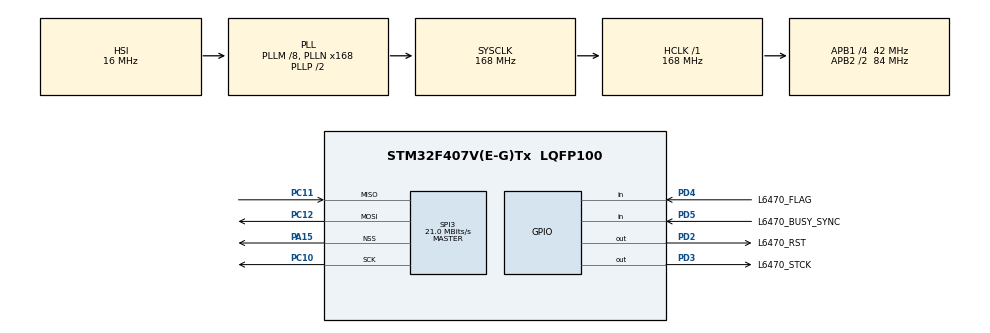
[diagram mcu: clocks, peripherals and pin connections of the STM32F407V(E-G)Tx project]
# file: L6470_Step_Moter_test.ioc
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Mcu.Family=STM32F4
Mcu.Name=STM32F407V(E-G)Tx
Mcu.Package=LQFP100
NVIC.PriorityGroup=NVIC_PRIORITYGROUP_4
PA13.Mode=Serial_Wire
PA13.Signal=SYS_JTMS-SWDIO
PA14.Mode=Serial_Wire
PA14.Signal=SYS_JTCK-SWCLK
PA15.Mode=NSS_Signal_Hard_Output
PA15.Signal=SPI3_NSS
PC10.Mode=Full_Duplex_Master
PC10.Signal=SPI3_SCK
PC11.Mode=Full_Duplex_Master
PC11.Signal=SPI3_MISO
PC12.Mode=Full_Duplex_Master
PC12.Signal=SPI3_MOSI
PC14-OSC32_IN.Mode=LSE-External-Clock-Source
PC14-OSC32_IN.Signal=RCC_OSC32_IN
PC15-OSC32_OUT.Mode=LSE-External-Clock-Source
PC15-OSC32_OUT.Signal=RCC_OSC32_OUT
PD2.GPIO_Label=L6470_RST
PD2.Signal=GPIO_Output
PD3.GPIO_Label=L6470_STCK
PD3.GPIO_Speed=GPIO_SPEED_FREQ_VERY_HIGH
PD3.Signal=GPIO_Output
PD4.GPIO_Label=L6470_FLAG
PD4.Signal=GPIO_Input
PD5.GPIO_Label=L6470_BUSY_SYNC
PD5.Signal=GPIO_Input
PH0-OSC_IN.Mode=HSE-External-Oscillator
PH0-OSC_IN.Signal=RCC_OSC_IN
PH1-OSC_OUT.Mode=HSE-External-Oscillator
PH1-OSC_OUT.Signal=RCC_OSC_OUT
ProjectManager.HeapSize=0x200
ProjectManager.StackSize=0x400
ProjectManager.TargetToolchain=STM32CubeIDE
RCC.48MHZClocksFreq_Value=84000000
RCC.AHBFreq_Value=168000000
RCC.APB1CLKDivider=RCC_HCLK_DIV4
RCC.APB1Freq_Value=42000000
RCC.APB1TimFreq_Value=84000000
RCC.APB2CLKDivider=RCC_HCLK_DIV2
RCC.APB2Freq_Value=84000000
RCC.APB2TimFreq_Value=168000000
RCC.CortexFreq_Value=168000000
RCC.HCLKFreq_Value=168000000
RCC.HSE_VALUE=8000000
RCC.HSI_VALUE=16000000
RCC.LSE_VALUE=32768
RCC.PLLM=8
RCC.PLLN=168
RCC.SYSCLKFreq_VALUE=168000000
RCC.SYSCLKSource=RCC_SYSCLKSOURCE_PLLCLK
RCC.VCOOutputFreq_Value=336000000
SPI3.CalculateBaudRate=21.0 MBits/s
SPI3.Direction=SPI_DIRECTION_2LINES
SPI3.Mode=SPI_MODE_MASTER
SPI3.VirtualNSS=VM_NSSHARD
SPI3.VirtualType=VM_MASTER
board=custom

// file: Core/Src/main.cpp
/* USER CODE BEGIN Header */
/**
  ******************************************************************************
  * @file           : main.c
  * @brief          : Main program body
  ******************************************************************************
  * @attention
  *
  * Copyright (c) 2023 STMicroelectronics.
  * All rights reserved.
  *
  * This software is licensed under terms that can be found in the LICENSE file
  * in the root directory of this software component.
  * If no LICENSE file comes with this software, it is provided AS-IS.
  *
  ******************************************************************************
  */
/* USER CODE END Header */
#include "main.h"

/* USER CODE BEGIN Includes */
#include <L6470.h>
/* USER CODE END Includes */

SPI_HandleTypeDef hspi3;

void SystemClock_Config(void);
static void MX_GPIO_Init(void);
static void MX_SPI3_Init(void);

int main(void)
{

  /* MCU Configuration--------------------------------------------------------*/

  /* Reset of all peripherals, Initializes the Flash interface and the Systick. */
  HAL_Init();

  /* Configure the system clock */
  SystemClock_Config();

  /* Initialize all configured peripherals */
  MX_GPIO_Init();
  MX_SPI3_Init();
  /* USER CODE BEGIN 2 */
  uint8_t dataToSend = 0b01100000;  // データを定義
  uint8_t data1= 0x01;
  uint8_t data2= 0x3f;
  uint8_t data3= 0xff;
  uint8_t data4= 0x38;
  /* USER CODE END 2 */

  /* Infinite loop */
  /* USER CODE BEGIN WHILE */
  while (1)
  {
	  HAL_SPI_Transmit(&hspi3, &data1, 1, 1000);
	  HAL_SPI_Transmit(&hspi3, &data2, 1, 1000);
	  HAL_SPI_Transmit(&hspi3, &data3, 1, 1000);
	  HAL_SPI_Transmit(&hspi3, &data4, 1, 1000);
	  if (HAL_SPI_Transmit(&hspi3, &dataToSend, 1, 1000) != HAL_OK) {
	    // ここにエラーハンドリングのコードを書く
	    Error_Handler();
	  }
	  HAL_Delay(1000);
    /* USER CODE END WHILE */

  }
}

void SystemClock_Config(void)
{
  RCC_OscInitTypeDef RCC_OscInitStruct = {0};
  RCC_ClkInitTypeDef RCC_ClkInitStruct = {0};

  /** Configure the main internal regulator output voltage
  */
  __HAL_RCC_PWR_CLK_ENABLE();
  __HAL_PWR_VOLTAGESCALING_CONFIG(PWR_REGULATOR_VOLTAGE_SCALE1);

  /** Initializes the RCC Oscillators according to the specified parameters
  * in the RCC_OscInitTypeDef structure.
  */
  RCC_OscInitStruct.OscillatorType = RCC_OSCILLATORTYPE_HSI;
  RCC_OscInitStruct.HSIState = RCC_HSI_ON;
  RCC_OscInitStruct.HSICalibrationValue = RCC_HSICALIBRATION_DEFAULT;
  RCC_OscInitStruct.PLL.PLLState = RCC_PLL_ON;
  RCC_OscInitStruct.PLL.PLLSource = RCC_PLLSOURCE_HSI;
  RCC_OscInitStruct.PLL.PLLM = 8;
  RCC_OscInitStruct.PLL.PLLN = 168;
  RCC_OscInitStruct.PLL.PLLP = RCC_PLLP_DIV2;
  RCC_OscInitStruct.PLL.PLLQ = 4;
  if (HAL_RCC_OscConfig(&RCC_OscInitStruct) != HAL_OK)
  {
    Error_Handler();
  }

  /** Initializes the CPU, AHB and APB buses clocks
  */
  RCC_ClkInitStruct.ClockType = RCC_CLOCKTYPE_HCLK|RCC_CLOCKTYPE_SYSCLK
                              |RCC_CLOCKTYPE_PCLK1|RCC_CLOCKTYPE_PCLK2;
  RCC_ClkInitStruct.SYSCLKSource = RCC_SYSCLKSOURCE_PLLCLK;
  RCC_ClkInitStruct.AHBCLKDivider = RCC_SYSCLK_DIV1;
  RCC_ClkInitStruct.APB1CLKDivider = RCC_HCLK_DIV4;
  RCC_ClkInitStruct.APB2CLKDivider = RCC_HCLK_DIV2;

  if (HAL_RCC_ClockConfig(&RCC_ClkInitStruct, FLASH_LATENCY_5) != HAL_OK)
  {
    Error_Handler();
  }
}

static void MX_SPI3_Init(void)
{

  /* SPI3 parameter configuration*/
  hspi3.Instance = SPI3;
  hspi3.Init.Mode = SPI_MODE_MASTER;
  hspi3.Init.Direction = SPI_DIRECTION_2LINES;
  hspi3.Init.DataSize = SPI_DATASIZE_8BIT;
  hspi3.Init.CLKPolarity = SPI_POLARITY_LOW;
  hspi3.Init.CLKPhase = SPI_PHASE_1EDGE;
  hspi3.Init.NSS = SPI_NSS_HARD_OUTPUT;
  hspi3.Init.BaudRatePrescaler = SPI_BAUDRATEPRESCALER_2;
  hspi3.Init.FirstBit = SPI_FIRSTBIT_MSB;
  hspi3.Init.TIMode = SPI_TIMODE_DISABLE;
  hspi3.Init.CRCCalculation = SPI_CRCCALCULATION_DISABLE;
  hspi3.Init.CRCPolynomial = 10;
  if (HAL_SPI_Init(&hspi3) != HAL_OK)
  {
    Error_Handler();
  }

}

static void MX_GPIO_Init(void)
{
  GPIO_InitTypeDef GPIO_InitStruct = {0};

  /* GPIO Ports Clock Enable */
  __HAL_RCC_GPIOC_CLK_ENABLE();
  __HAL_RCC_GPIOH_CLK_ENABLE();
  __HAL_RCC_GPIOA_CLK_ENABLE();
  __HAL_RCC_GPIOD_CLK_ENABLE();

  /*Configure GPIO pin Output Level */
  HAL_GPIO_WritePin(GPIOD, L6470_RST_Pin|L6470_STCK_Pin, GPIO_PIN_RESET);

  /*Configure GPIO pin : L6470_RST_Pin */
  GPIO_InitStruct.Pin = L6470_RST_Pin;
  GPIO_InitStruct.Mode = GPIO_MODE_OUTPUT_PP;
  GPIO_InitStruct.Pull = GPIO_NOPULL;
  GPIO_InitStruct.Speed = GPIO_SPEED_FREQ_LOW;
  HAL_GPIO_Init(L6470_RST_GPIO_Port, &GPIO_InitStruct);

  /*Configure GPIO pin : L6470_STCK_Pin */
  GPIO_InitStruct.Pin = L6470_STCK_Pin;
  GPIO_InitStruct.Mode = GPIO_MODE_OUTPUT_PP;
  GPIO_InitStruct.Pull = GPIO_NOPULL;
  GPIO_InitStruct.Speed = GPIO_SPEED_FREQ_VERY_HIGH;
  HAL_GPIO_Init(L6470_STCK_GPIO_Port, &GPIO_InitStruct);

  /*Configure GPIO pins : L6470_FLAG_Pin L6470_BUSY_SYNC_Pin */
  GPIO_InitStruct.Pin = L6470_FLAG_Pin|L6470_BUSY_SYNC_Pin;
  GPIO_InitStruct.Mode = GPIO_MODE_INPUT;
  GPIO_InitStruct.Pull = GPIO_NOPULL;
  HAL_GPIO_Init(GPIOD, &GPIO_InitStruct);

}

void Error_Handler(void)
{
  __disable_irq();
  while (1)
  {
  }
}
